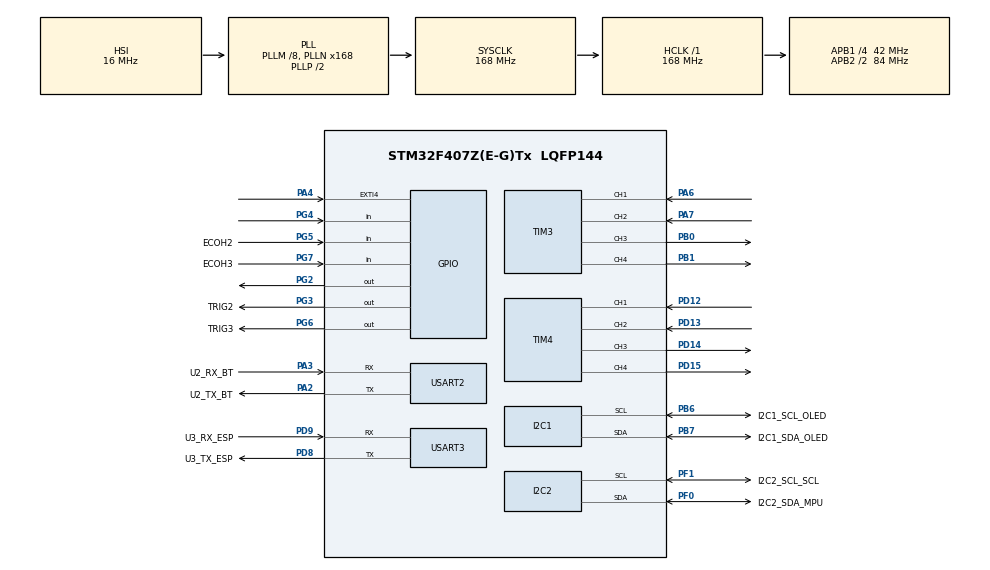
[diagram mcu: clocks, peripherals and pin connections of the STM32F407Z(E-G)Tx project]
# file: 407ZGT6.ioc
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FREERTOS.Tasks01=defaultTask,24,128,StartDefaultTask,Default,NULL,Dynamic,NULL,NULL
Mcu.Family=STM32F4
Mcu.Name=STM32F407Z(E-G)Tx
Mcu.Package=LQFP144
NVIC.PriorityGroup=NVIC_PRIORITYGROUP_4
NVIC.TIM1_UP_TIM10_IRQn=true\:15\:0\:false\:false\:true\:false\:false\:true\:true
NVIC.TimeBase=TIM1_UP_TIM10_IRQn
NVIC.TimeBaseIP=TIM1
PA13.Mode=Serial_Wire
PA13.Signal=SYS_JTMS-SWDIO
PA14.Mode=Serial_Wire
PA14.Signal=SYS_JTCK-SWCLK
PA2.GPIO_Label=U2_TX_BT
PA2.Mode=Asynchronous
PA2.Signal=USART2_TX
PA3.GPIO_Label=U2_RX_BT
PA3.Mode=Asynchronous
PA3.Signal=USART2_RX
PA4.Signal=GPXTI4
PA6.Signal=S_TIM3_CH1
PA7.Signal=S_TIM3_CH2
PB0.Signal=S_TIM3_CH3
PB1.Signal=S_TIM3_CH4
PB6.GPIO_Label=I2C1_SCL_OLED
PB6.Mode=I2C
PB6.Signal=I2C1_SCL
PB7.GPIO_Label=I2C1_SDA_OLED
PB7.Mode=I2C
PB7.Signal=I2C1_SDA
PC14-OSC32_IN.Mode=LSE-External-Oscillator
PC14-OSC32_IN.Signal=RCC_OSC32_IN
PC15-OSC32_OUT.Mode=LSE-External-Oscillator
PC15-OSC32_OUT.Signal=RCC_OSC32_OUT
PD12.Signal=S_TIM4_CH1
PD13.Signal=S_TIM4_CH2
PD14.Signal=S_TIM4_CH3
PD15.Signal=S_TIM4_CH4
PD8.GPIO_Label=U3_TX_ESP
PD8.Mode=Asynchronous
PD8.Signal=USART3_TX
PD9.GPIO_Label=U3_RX_ESP
PD9.Mode=Asynchronous
PD9.Signal=USART3_RX
PF0.GPIO_Label=I2C2_SDA_MPU
PF0.Mode=I2C
PF0.Signal=I2C2_SDA
PF1.GPIO_Label=I2C2_SCL_SCL
PF1.Mode=I2C
PF1.Signal=I2C2_SCL
PG2.Signal=GPIO_Output
PG3.GPIO_Label=TRIG2
PG3.Signal=GPIO_Output
PG4.Signal=GPIO_Input
PG5.GPIO_Label=ECOH2
PG5.Signal=GPIO_Input
PG6.GPIO_Label=TRIG3
PG6.Signal=GPIO_Output
PG7.GPIO_Label=ECOH3
PG7.Signal=GPIO_Input
PH0-OSC_IN.Mode=HSE-External-Oscillator
PH0-OSC_IN.Signal=RCC_OSC_IN
PH1-OSC_OUT.Mode=HSE-External-Oscillator
PH1-OSC_OUT.Signal=RCC_OSC_OUT
ProjectManager.HeapSize=0x200
ProjectManager.StackSize=0x400
ProjectManager.TargetToolchain=MDK-ARM V5.32
RCC.48MHZClocksFreq_Value=84000000
RCC.AHBFreq_Value=168000000
RCC.APB1CLKDivider=RCC_HCLK_DIV4
RCC.APB1Freq_Value=42000000
RCC.APB1TimFreq_Value=84000000
RCC.APB2CLKDivider=RCC_HCLK_DIV2
RCC.APB2Freq_Value=84000000
RCC.APB2TimFreq_Value=168000000
RCC.CortexFreq_Value=168000000
RCC.HCLKFreq_Value=168000000
RCC.HSE_VALUE=25000000
RCC.HSI_VALUE=16000000
RCC.PLLM=8
RCC.PLLN=168
RCC.SYSCLKFreq_VALUE=168000000
RCC.SYSCLKSource=RCC_SYSCLKSOURCE_PLLCLK
RCC.VCOOutputFreq_Value=336000000
SH.S_TIM3_CH1.0=TIM3_CH1,Encoder_Interface
SH.S_TIM3_CH2.0=TIM3_CH2,Encoder_Interface
SH.S_TIM3_CH3.0=TIM3_CH3,PWM Generation3 CH3
SH.S_TIM3_CH4.0=TIM3_CH4,PWM Generation4 CH4
SH.S_TIM4_CH1.0=TIM4_CH1,Encoder_Interface
SH.S_TIM4_CH2.0=TIM4_CH2,Encoder_Interface
SH.S_TIM4_CH3.0=TIM4_CH3,PWM Generation3 CH3
SH.S_TIM4_CH4.0=TIM4_CH4,PWM Generation4 CH4
TIM3.Channel-PWM\ Generation3\ CH3=TIM_CHANNEL_3
TIM3.Channel-PWM\ Generation4\ CH4=TIM_CHANNEL_4
TIM4.Channel-PWM\ Generation3\ CH3=TIM_CHANNEL_3
TIM4.Channel-PWM\ Generation4\ CH4=TIM_CHANNEL_4
USART2.VirtualMode=VM_ASYNC
USART3.VirtualMode=VM_ASYNC
VP_FREERTOS_VS_CMSIS_V2.Mode=CMSIS_V2
VP_SYS_VS_tim1.Mode=TIM1
board=custom

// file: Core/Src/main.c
/* USER CODE BEGIN Header */
/**
 ******************************************************************************
 * @file           : main.c
 * @brief          : Main program body
 ******************************************************************************
 * @attention
 *
 * Copyright (c) 2024 STMicroelectronics.
 * All rights reserved.
 *
 * This software is licensed under terms that can be found in the LICENSE file
 * in the root directory of this software component.
 * If no LICENSE file comes with this software, it is provided AS-IS.
 *
 ******************************************************************************
 */
/* USER CODE END Header */
#include "main.h"
#include "cmsis_os.h"
#include "i2c.h"
#include "tim.h"
#include "usart.h"
#include "gpio.h"

void SystemClock_Config(void);
void MX_FREERTOS_Init(void);

int main(void)
{

  /* MCU Configuration--------------------------------------------------------*/

  /* Reset of all peripherals, Initializes the Flash interface and the Systick. */
  HAL_Init();

  /* Configure the system clock */
  SystemClock_Config();

  /* Initialize all configured peripherals */
  MX_GPIO_Init();
  MX_TIM3_Init();
  MX_I2C1_Init();
  MX_I2C2_Init();
  MX_USART2_UART_Init();
  MX_USART3_UART_Init();
  MX_TIM4_Init();
  /* USER CODE BEGIN 2 */
  HAL_TIM_PWM_Start(&htim3, TIM_CHANNEL_1);
  HAL_TIM_PWM_Start(&htim3, TIM_CHANNEL_2);
  __HAL_TIM_SetCompare(&htim3, TIM_CHANNEL_1, 0);
  __HAL_TIM_SetCompare(&htim3, TIM_CHANNEL_2, 65536 / 2);
  /* USER CODE END 2 */

  /* Init scheduler */
  osKernelInitialize();

  /* Call init function for freertos objects (in cmsis_os2.c) */
  MX_FREERTOS_Init();

  /* Start scheduler */
  osKernelStart();

  /* We should never get here as control is now taken by the scheduler */

  /* Infinite loop */
  while (1)
  {

  }
}

void SystemClock_Config(void)
{
  RCC_OscInitTypeDef RCC_OscInitStruct = {0};
  RCC_ClkInitTypeDef RCC_ClkInitStruct = {0};

  /** Configure the main internal regulator output voltage
  */
  __HAL_RCC_PWR_CLK_ENABLE();
  __HAL_PWR_VOLTAGESCALING_CONFIG(PWR_REGULATOR_VOLTAGE_SCALE1);

  /** Initializes the RCC Oscillators according to the specified parameters
  * in the RCC_OscInitTypeDef structure.
  */
  RCC_OscInitStruct.OscillatorType = RCC_OSCILLATORTYPE_HSI;
  RCC_OscInitStruct.HSIState = RCC_HSI_ON;
  RCC_OscInitStruct.HSICalibrationValue = RCC_HSICALIBRATION_DEFAULT;
  RCC_OscInitStruct.PLL.PLLState = RCC_PLL_ON;
  RCC_OscInitStruct.PLL.PLLSource = RCC_PLLSOURCE_HSI;
  RCC_OscInitStruct.PLL.PLLM = 8;
  RCC_OscInitStruct.PLL.PLLN = 168;
  RCC_OscInitStruct.PLL.PLLP = RCC_PLLP_DIV2;
  RCC_OscInitStruct.PLL.PLLQ = 4;
  if (HAL_RCC_OscConfig(&RCC_OscInitStruct) != HAL_OK)
  {
    Error_Handler();
  }

  /** Initializes the CPU, AHB and APB buses clocks
  */
  RCC_ClkInitStruct.ClockType = RCC_CLOCKTYPE_HCLK|RCC_CLOCKTYPE_SYSCLK
                              |RCC_CLOCKTYPE_PCLK1|RCC_CLOCKTYPE_PCLK2;
  RCC_ClkInitStruct.SYSCLKSource = RCC_SYSCLKSOURCE_PLLCLK;
  RCC_ClkInitStruct.AHBCLKDivider = RCC_SYSCLK_DIV1;
  RCC_ClkInitStruct.APB1CLKDivider = RCC_HCLK_DIV4;
  RCC_ClkInitStruct.APB2CLKDivider = RCC_HCLK_DIV2;

  if (HAL_RCC_ClockConfig(&RCC_ClkInitStruct, FLASH_LATENCY_5) != HAL_OK)
  {
    Error_Handler();
  }
}

void HAL_TIM_PeriodElapsedCallback(TIM_HandleTypeDef *htim)
{
  if (htim->Instance == TIM1) {
    HAL_IncTick();
  }
}

void Error_Handler(void)
{
  __disable_irq();
  while (1)
  {
  }
}
